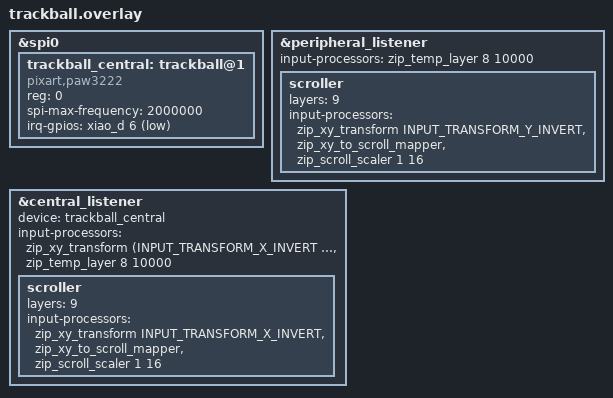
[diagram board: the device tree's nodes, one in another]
&spi0 {
    status = "okay";

    trackball_central: trackball@1 {
        status = "okay";
        compatible = "pixart,paw3222";
        reg = <0>;
        spi-max-frequency = <2000000>;
        irq-gpios = <&xiao_d 6 (GPIO_ACTIVE_LOW | GPIO_PULL_UP)>;
    };
};

// ペリフェラル（split経由）のリスナーを有効化
// （XY反転はペリフェラル側 trackball_split で適用済み）
&peripheral_listener {
    status = "okay";
    input-processors =
        <&zip_temp_layer 8 10000>;  // 8 = MOUS（マウス移動レイヤーを自動有効化）

    scroller {
        layers = <9>;               // 9 = SCRL（スクロールレイヤー）
        input-processors =
            <&zip_xy_transform INPUT_TRANSFORM_Y_INVERT>,  // 左TBスクロールの上下反転を解消
            <&zip_xy_to_scroll_mapper>,
            <&zip_scroll_scaler 1 16>;
    };
};

// セントラルのリスナーを有効化し、deviceを紐付け
&central_listener {
    status = "okay";
    device = <&trackball_central>;
    input-processors =
        <&zip_xy_transform (INPUT_TRANSFORM_X_INVERT | INPUT_TRANSFORM_Y_INVERT)>,
        <&zip_temp_layer 8 10000>;  // 8 = MOUS（マウス移動レイヤーを自動有効化）

    scroller {
        layers = <9>;               // 9 = SCRL（スクロールレイヤー）
        input-processors =
            <&zip_xy_transform INPUT_TRANSFORM_X_INVERT>,  // 右TBスクロールの左右反転を解消
            <&zip_xy_to_scroll_mapper>,
            <&zip_scroll_scaler 1 16>;
    };
};
